# TM4C1294NCPDT register map
Vendor: Texas Instruments; File version: 2.2.0.295
CPU: CM4 r0p1, little endian, MPU, FPU, 3 interrupt priority bits
Registers are 32-bit, read-write, no defined reset value unless marked. A register's access mark holds for its fields unless they carry their own. Offsets are from the block's base; [hi:lo] are bit positions; lines under a group give offsets from that group; {n}, {i} and the like mark numbered series; 'fields as' and 'values as' point back to an identical list.

## NVIC — NVIC (NVIC)
Base 0xE000E000
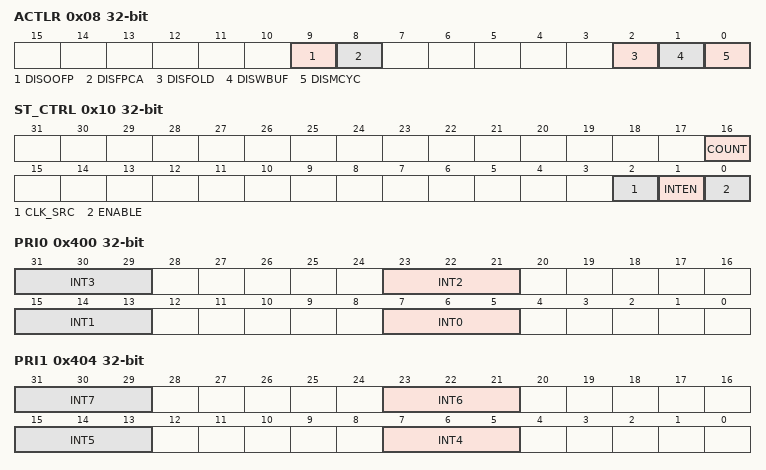
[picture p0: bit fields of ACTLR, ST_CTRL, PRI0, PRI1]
0x08 ACTLR
  [9] DISOOFP — Disable Out-Of-Order Floating
  [8] DISFPCA — Disable CONTROL
  [2] DISFOLD — Disable IT Folding
  [1] DISWBUF — Disable Write Buffer
  [0] DISMCYC — Disable Interrupts of Multiple
0x10 ST_CTRL
  [16] COUNT — Count Flag
  [2] CLK_SRC — Clock Source
  [1] INTEN — Interrupt Enable
  [0] ENABLE
0x14 ST_RELOAD
  [23:0] VALUE — Reload Value
0x18 ST_CURRENT
  [23:0] VALUE — Current Value
{0x100+4i} EN{i} (i=0..3)
  [31:0] INT — Interrupt Enable
{0x180+4i} DIS{i} (i=0..3)
  [31:0] INT — Interrupt Disable
{0x200+4i} PEND{i} (i=0..3)
  [31:0] INT — Interrupt Set Pending
{0x280+4i} UNPEND{i} (i=0..3)
  [31:0] INT — Interrupt Clear Pending
{0x300+4i} ACTIVE{i} (i=0..3)
  [31:0] INT — Interrupt Active
0x400 PRI0
  [8n+7:8n+5] INT{n} (n=0..3) — Interrupt {n} Priority Mask
0x404 PRI1
  [8n-25:8n-27] INT{n} (n=4..7) — Interrupt {n} Priority Mask
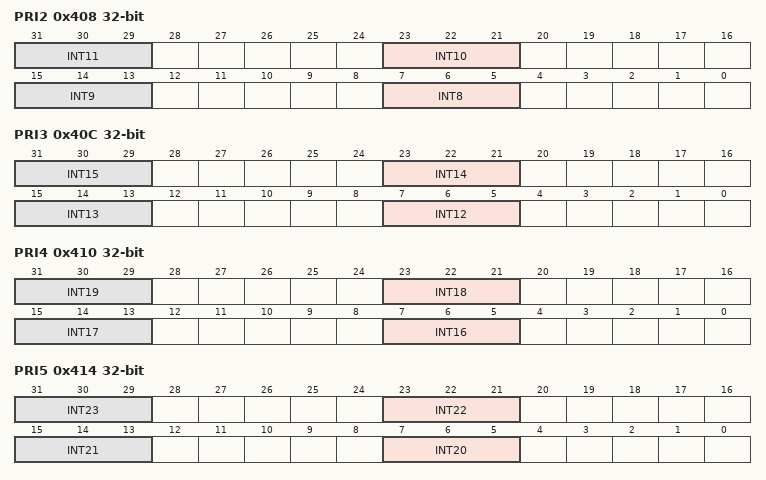
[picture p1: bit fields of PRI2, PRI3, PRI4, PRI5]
0x408 PRI2
  [8n-57:8n-59] INT{n} (n=8..11) — Interrupt {n} Priority Mask
0x40C PRI3
  [8n-89:8n-91] INT{n} (n=12..15) — Interrupt {n} Priority Mask
0x410 PRI4
  [8n-121:8n-123] INT{n} (n=16..19) — Interrupt {n} Priority Mask
0x414 PRI5
  [8n-153:8n-155] INT{n} (n=20..23) — Interrupt {n} Priority Mask
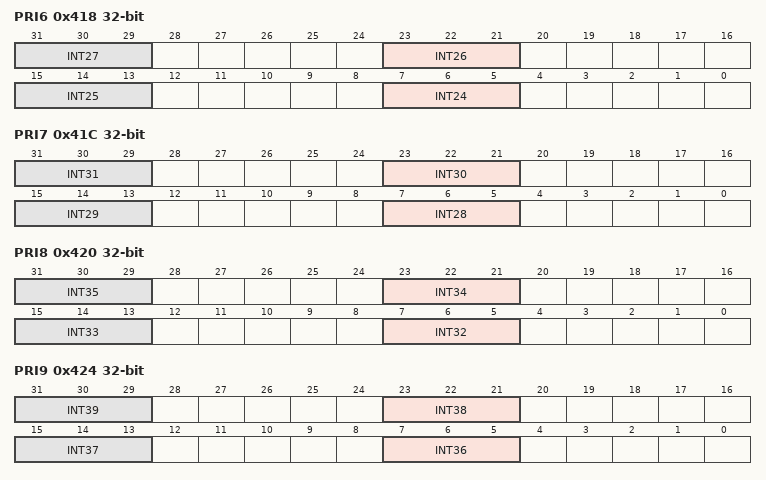
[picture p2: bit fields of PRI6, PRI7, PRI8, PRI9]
0x418 PRI6
  [8n-185:8n-187] INT{n} (n=24..27) — Interrupt {n} Priority Mask
0x41C PRI7
  [8n-217:8n-219] INT{n} (n=28..31) — Interrupt {n} Priority Mask
0x420 PRI8
  [8n-249:8n-251] INT{n} (n=32..35) — Interrupt {n} Priority Mask
0x424 PRI9
  [8n-281:8n-283] INT{n} (n=36..39) — Interrupt {n} Priority Mask
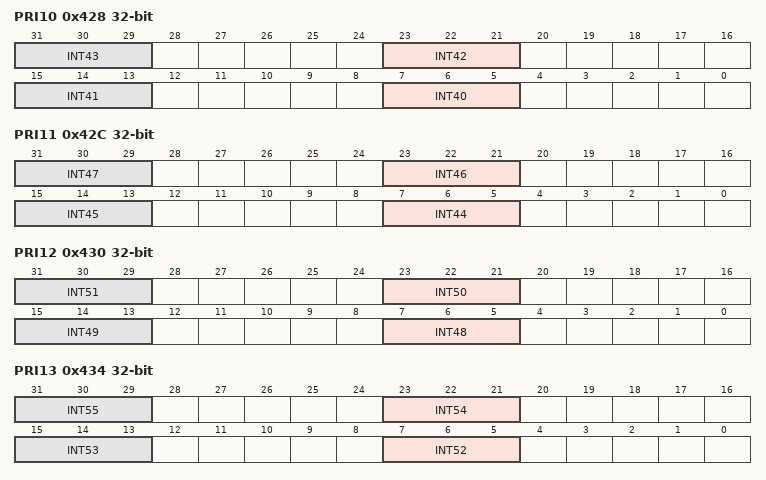
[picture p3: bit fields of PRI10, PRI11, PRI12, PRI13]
0x428 PRI10
  [8n-313:8n-315] INT{n} (n=40..43) — Interrupt {n} Priority Mask
0x42C PRI11
  [8n-345:8n-347] INT{n} (n=44..47) — Interrupt {n} Priority Mask
0x430 PRI12
  [8n-377:8n-379] INT{n} (n=48..51) — Interrupt {n} Priority Mask
0x434 PRI13
  [8n-409:8n-411] INT{n} (n=52..55) — Interrupt {n} Priority Mask
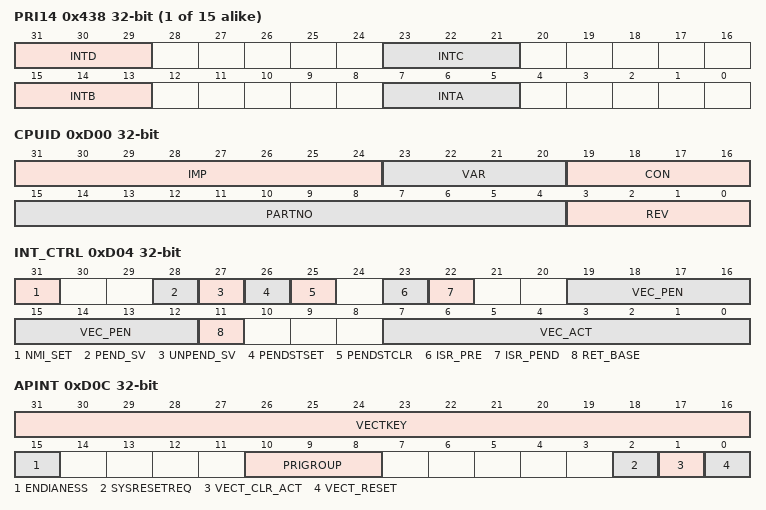
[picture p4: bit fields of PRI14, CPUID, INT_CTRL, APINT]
{0x400+4i} PRI{i} (i=14..28)
  [31:29] INTD — Interrupt {4i+3} Priority Mask
  [23:21] INTC — Interrupt {4i+2} Priority Mask
  [15:13] INTB — Interrupt {4i+1} Priority Mask
  [7:5] INTA — Interrupt {4i} Priority Mask
0xD00 CPUID
  [31:24] IMP — Implementer Code
    65=ARM
  [23:20] VAR — Variant Number
  [19:16] CON — Constant
  [15:4] PARTNO — Part Number
    0xC24=CM4 (Cortex-M4 processor)
  [3:0] REV — Revision Number
0xD04 INT_CTRL
  [31] NMI_SET — NMI Set Pending
  [28] PEND_SV — PendSV Set Pending
  [27] UNPEND_SV — PendSV Clear Pending
  [26] PENDSTSET — SysTick Set Pending
  [25] PENDSTCLR — SysTick Clear Pending
  [23] ISR_PRE — Debug Interrupt Handling
  [22] ISR_PEND — Interrupt Pending
  [19:12] VEC_PEN — Interrupt Pending Vector Number
    2=NMI; 3=HARD (Hard fault); 4=MEM (Memory management fault); 5=BUS (Bus fault); 6=USG (Usage fault); 11=SVC (SVCall); 14=PNDSV (PendSV); 15=TICK (SysTick)
  [11] RET_BASE — Return to Base
  [7:0] VEC_ACT — Interrupt Pending Vector Number
0xD08 VTABLE
  [31:10] OFFSET — Vector Table Offset
0xD0C APINT
  [31:16] VECTKEY — Register Key
  [15] ENDIANESS — Data Endianess
  [10:8] PRIGROUP — Interrupt Priority Grouping
    0=7_1 (Priority group 7.1 split); 1=6_2 (Priority group 6.2 split); 2=5_3 (Priority group 5.3 split); 3=4_4 (Priority group 4.4 split); 4=3_5 (Priority group 3.5 split); 5=2_6 (Priority group 2.6 split); 6=1_7 (Priority group 1.7 split); 7=0_8 (Priority group 0.8 split)
  [2] SYSRESETREQ — System Reset Request
  [1] VECT_CLR_ACT — Clear Active NMI / Fault
  [0] VECT_RESET — System Reset
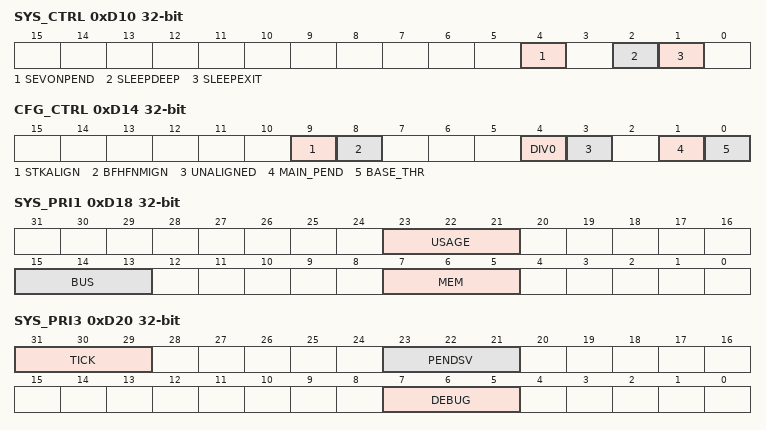
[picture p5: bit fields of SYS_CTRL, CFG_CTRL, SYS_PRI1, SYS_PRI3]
0xD10 SYS_CTRL
  [4] SEVONPEND — Wake Up on Pending
  [2] SLEEPDEEP — Deep Sleep Enable
  [1] SLEEPEXIT — Sleep on ISR Exit
0xD14 CFG_CTRL
  [9] STKALIGN — Stack Alignment on Exception
  [8] BFHFNMIGN — Ignore Bus Fault in NMI and
  [4] DIV0 — Trap on Divide by 0
  [3] UNALIGNED — Trap on Unaligned Access
  [1] MAIN_PEND — Allow Main Interrupt Trigger
  [0] BASE_THR — Thread State Control
0xD18 SYS_PRI1
  [23:21] USAGE — Usage Fault Priority
  [15:13] BUS — Bus Fault Priority
  [7:5] MEM — Memory Management Fault Priority
0xD1C SYS_PRI2
  [31:29] SVC — SVCall Priority
0xD20 SYS_PRI3
  [31:29] TICK — SysTick Exception Priority
  [23:21] PENDSV — PendSV Priority
  [7:5] DEBUG — Debug Priority
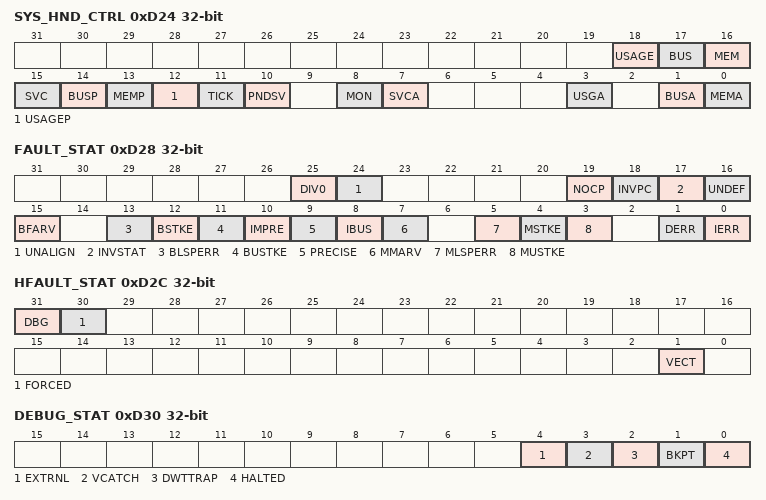
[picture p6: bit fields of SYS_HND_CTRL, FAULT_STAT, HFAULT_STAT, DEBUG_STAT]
0xD24 SYS_HND_CTRL
  [18] USAGE — Usage Fault Enable
  [17] BUS — Bus Fault Enable
  [16] MEM — Memory Management Fault Enable
  [15] SVC — SVC Call Pending
  [14] BUSP — Bus Fault Pending
  [13] MEMP — Memory Management Fault Pending
  [12] USAGEP — Usage Fault Pending
  [11] TICK — SysTick Exception Active
  [10] PNDSV — PendSV Exception Active
  [8] MON — Debug Monitor Active
  [7] SVCA — SVC Call Active
  [3] USGA — Usage Fault Active
  [1] BUSA — Bus Fault Active
  [0] MEMA — Memory Management Fault Active
0xD28 FAULT_STAT
  [25] DIV0 — Divide-by-Zero Usage Fault
  [24] UNALIGN — Unaligned Access Usage Fault
  [19] NOCP — No Coprocessor Usage Fault
  [18] INVPC — Invalid PC Load Usage Fault
  [17] INVSTAT — Invalid State Usage Fault
  [16] UNDEF — Undefined Instruction Usage
  [15] BFARV — Bus Fault Address Register Valid
  [13] BLSPERR — Bus Fault on Floating-Point Lazy
  [12] BSTKE — Stack Bus Fault
  [11] BUSTKE — Unstack Bus Fault
  [10] IMPRE — Imprecise Data Bus Error
  [9] PRECISE — Precise Data Bus Error
  [8] IBUS — Instruction Bus Error
  [7] MMARV — Memory Management Fault Address
  [5] MLSPERR — Memory Management Fault on
  [4] MSTKE — Stack Access Violation
  [3] MUSTKE — Unstack Access Violation
  [1] DERR — Data Access Violation
  [0] IERR — Instruction Access Violation
0xD2C HFAULT_STAT
  [31] DBG — Debug Event
  [30] FORCED — Forced Hard Fault
  [1] VECT — Vector Table Read Fault
0xD30 DEBUG_STAT
  [4] EXTRNL — EDBGRQ asserted
  [3] VCATCH — Vector catch
  [2] DWTTRAP — DWT match
  [1] BKPT — Breakpoint instruction
  [0] HALTED — Halt request
0xD34 MM_ADDR
  [31:0] VALUE — Fault Address
0xD38 FAULT_ADDR
  [31:0] VALUE — Fault Address
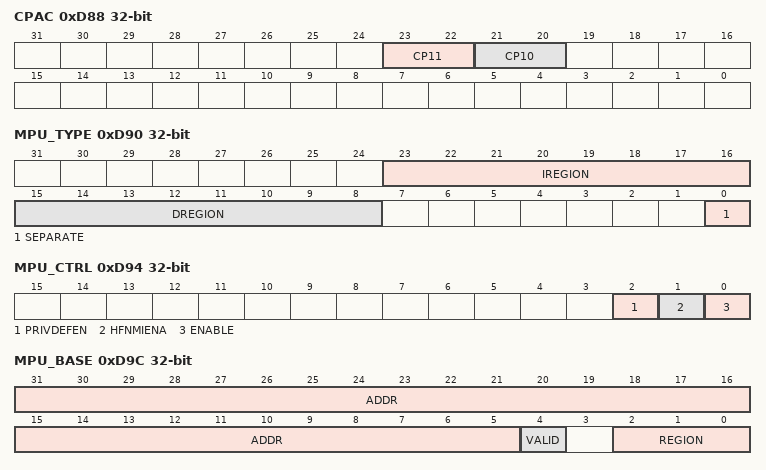
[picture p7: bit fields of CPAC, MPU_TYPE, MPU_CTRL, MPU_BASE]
0xD88 CPAC
  [23:22] CP11 — CP11 Coprocessor Access
    0=DIS (Access Denied); 1=PRIV (Privileged Access Only); 3=FULL (Full Access)
  [21:20] CP10 — CP10 Coprocessor Access
    values as CP11
0xD90 MPU_TYPE
  [23:16] IREGION — Number of I Regions
  [15:8] DREGION — Number of D Regions
  [0] SEPARATE — Separate or Unified MPU
0xD94 MPU_CTRL
  [2] PRIVDEFEN — MPU Default Region
  [1] HFNMIENA — MPU Enabled During Faults
  [0] ENABLE — MPU Enable
0xD98 MPU_NUMBER
  [2:0] VALUE — MPU Region to Access
0xD9C MPU_BASE
  [31:5] ADDR — Base Address Mask
  [4] VALID — Region Number Valid
  [2:0] REGION — Region Number
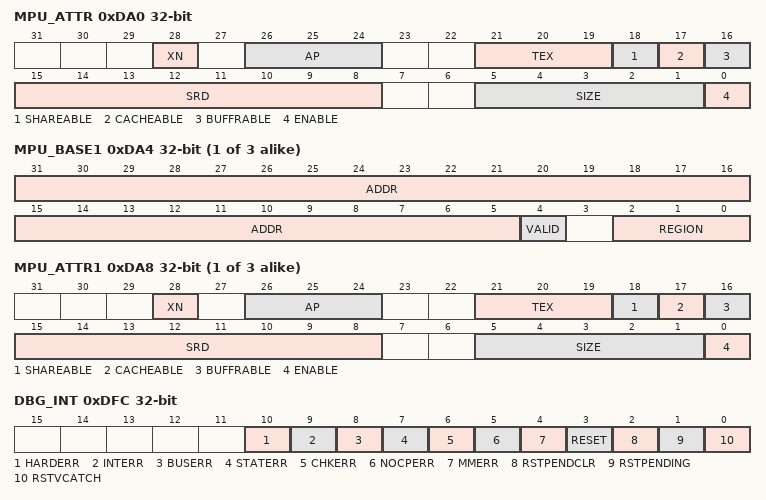
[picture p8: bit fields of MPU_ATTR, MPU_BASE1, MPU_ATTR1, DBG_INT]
0xDA0 MPU_ATTR
  [28] XN — Instruction Access Disable
  [26:24] AP — Access Privilege
  [21:19] TEX — Type Extension Mask
  [18] SHAREABLE
  [17] CACHEABLE
  [16] BUFFRABLE — Bufferable
  [15:8] SRD — Subregion Disable Bits
  [5:1] SIZE — Region Size Mask
  [0] ENABLE — Region Enable
{0xD9C+8i} MPU_BASE{i} (i=1..3)
  fields as MPU_BASE
{0xDA0+8i} MPU_ATTR{i} (i=1..3)
  fields as MPU_ATTR
0xDF0 DBG_CTRL
  [25] S_RESET_ST — Core has reset since last read
  [24] S_RETIRE_ST — Core has executed insruction
  [19] S_LOCKUP — Core is locked up
  [18] S_SLEEP — Core is sleeping
  [17] S_HALT — Core status on halt
  [31:16] DBGKEY — Debug key mask
  [16] S_REGRDY — Register read/write available
  [5] C_SNAPSTALL — Breaks a stalled load/store
  [3] C_MASKINT — Mask interrupts when stepping
  [2] C_STEP — Step the core
  [1] C_HALT — Halt the core
  [0] C_DEBUGEN — Enable debug
0xDF4 DBG_XFER
  [16] REG_WNR — Write or not read
  [4] REG_FLAGS — xPSR/Flags register
  [3] REG_R8 — Register R8
  [2] REG_R4 — Register R4
  [3:2] REG_R12 — Register R12
  [1] REG_R2 — Register R2
  [2:1] REG_R6 — Register R6
  [3:1] REG_R14 — Register R14
  [4:0] REG_SEL — Register
  [0] REG_R1 — Register R1
  [1:0] REG_R3 — Register R3
  [2:0] REG_R7 — Register R7
  [3:0] REG_R15 — Register R15
0xDF8 DBG_DATA
  [31:0] VALUE — Data temporary cache
0xDFC DBG_INT
  [10] HARDERR — Debug trap on hard fault
  [9] INTERR — Debug trap on interrupt errors
  [8] BUSERR — Debug trap on bus error
  [7] STATERR — Debug trap on usage fault state
  [6] CHKERR — Debug trap on usage fault check
  [5] NOCPERR — Debug trap on coprocessor error
  [4] MMERR — Debug trap on mem manage fault
  [3] RESET — Core reset status
  [2] RSTPENDCLR — Clear pending core reset
  [1] RSTPENDING — Core reset is pending
  [0] RSTVCATCH — Reset vector catch
0xF00 SW_TRIG
  [7:0] INTID — Interrupt ID
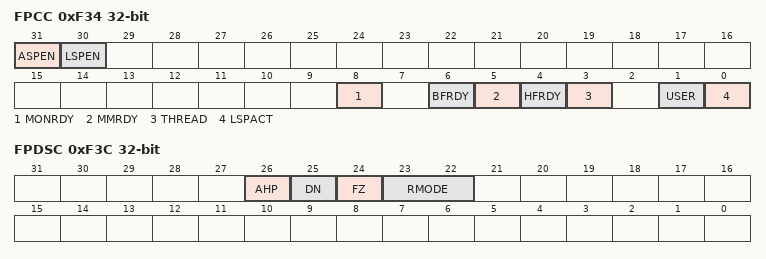
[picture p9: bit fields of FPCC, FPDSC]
0xF34 FPCC
  [31] ASPEN — Automatic State Preservation
  [30] LSPEN — Lazy State Preservation Enable
  [8] MONRDY — Monitor Ready
  [6] BFRDY — Bus Fault Ready
  [5] MMRDY — Memory Management Fault Ready
  [4] HFRDY — Hard Fault Ready
  [3] THREAD — Thread Mode
  [1] USER — User Privilege Level
  [0] LSPACT — Lazy State Preservation Active
0xF38 FPCA
  [31:3] ADDRESS
0xF3C FPDSC
  [26] AHP — AHP Bit Default
  [25] DN — DN Bit Default
  [24] FZ — FZ Bit Default
  [23:22] RMODE — RMODE Bit Default
    0=RN (Round to Nearest (RN) mode); 1=RP (Round towards Plus Infinity (RP)); 2=RM (Round towards Minus Infinity); 3=RZ (Round towards Zero (RZ) mode)
